# STM32H7A3x register map
File version: 1.8
CPU: CM7 r0p1, little endian, MPU, FPU, 4 interrupt priority bits
Registers are 32-bit, read-write, reset 0x0 unless marked. A register's access mark holds for its fields unless they carry their own. Offsets are from the block's base; [hi:lo] are bit positions; {n}, {i} and the like mark numbered series.

## DBGMCU — Microcontroller Debug Unit
Base 0x5C001000
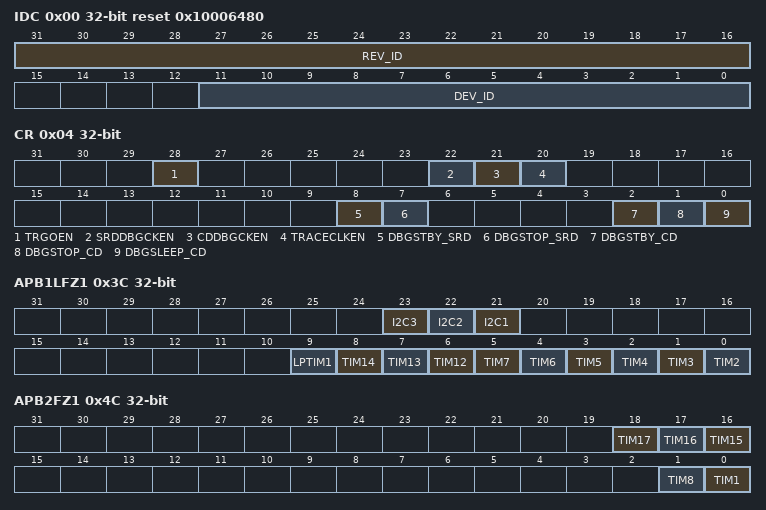
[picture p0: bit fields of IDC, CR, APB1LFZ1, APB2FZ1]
0x00 IDC ro reset 0x10006480 — DBGMCU Identity Code Register
  [31:16] REV_ID — Revision
  [11:0] DEV_ID — Device ID
0x04 CR — DBGMCU Configuration Register
  [28] TRGOEN — External trigger output enable
  [22] SRDDBGCKEN — SmartRun domain debug clock enable
  [21] CDDBGCKEN — CPU domain debug clock enable
  [20] TRACECLKEN — Trace port clock enable
  [8] DBGSTBY_SRD — debug in SmartRun domain Standby mode
  [7] DBGSTOP_SRD — debug in SmartRun domain Stop mode
  [2] DBGSTBY_CD — Allow D1 domain debug in Standby mode
  [1] DBGSTOP_CD — Allow D1 domain debug in Stop mode
  [0] DBGSLEEP_CD — Allow D1 domain debug in Sleep mode
0x34 APB3FZ1 — DBGMCU APB3 peripheral freeze register
  [6] WWDG — WWDG stop in debug
0x3C APB1LFZ1 — DBGMCU APB1L peripheral freeze register
  [23] I2C3 — I2C3 SMBUS timeout stop in debug
  [22] I2C2 — I2C2 SMBUS timeout stop in debug
  [21] I2C1 — I2C1 SMBUS timeout stop in debug
  [9] LPTIM1 — LPTIM1 stop in debug
  [8] TIM14 — TIM14 stop in debug
  [7] TIM13 — TIM13 stop in debug
  [6] TIM12 — TIM12 stop in debug
  [n-2] TIM{n} (n=2..7) — TIM{n} stop in debug
0x4C APB2FZ1 — DBGMCU APB2 peripheral freeze register
  [18] TIM17 — TIM17 stop in debug
  [17] TIM16 — TIM16 stop in debug
  [16] TIM15 — TIM15 stop in debug
  [1] TIM8 — TIM8 stop in debug
  [0] TIM1 — TIM1 stop in debug
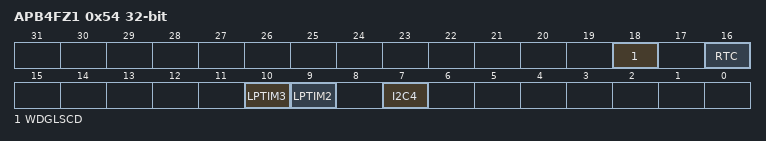
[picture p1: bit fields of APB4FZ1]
0x54 APB4FZ1 — DBGMCU APB4 peripheral freeze register
  [18] WDGLSCD — LS watchdog for CPU domain stop in debug
  [16] RTC — RTC stop in debug
  [10] LPTIM3 — LPTIM3 stop in debug
  [9] LPTIM2 — LPTIM2 stop in debug
  [7] I2C4 — I2C4 SMBUS timeout stop in debug

## MPU — Memory protection unit
Base 0xE000ED90
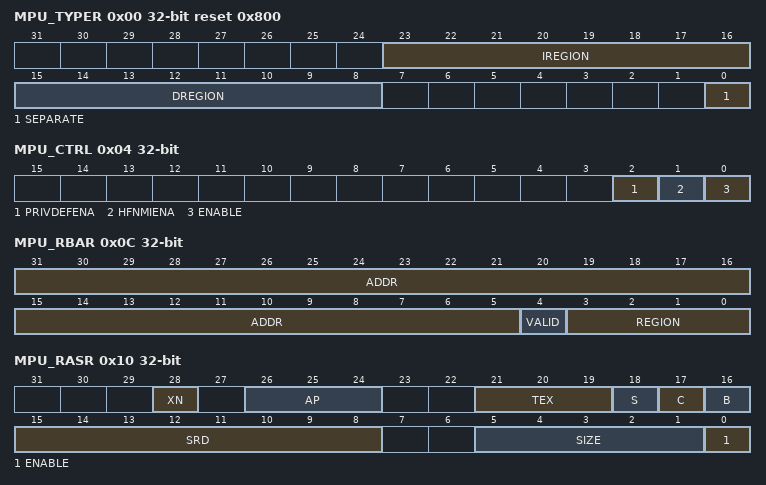
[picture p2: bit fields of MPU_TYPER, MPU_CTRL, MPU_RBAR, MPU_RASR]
0x00 MPU_TYPER ro reset 0x800 — MPU type register
  [23:16] IREGION — Number of MPU instruction regions
  [15:8] DREGION — Number of MPU data regions
  [0] SEPARATE — Separate flag
0x04 MPU_CTRL — MPU control register
  [2] PRIVDEFENA — Enable priviliged software access to default memory map
  [1] HFNMIENA — Enables the operation of MPU during hard fault
  [0] ENABLE — Enables the MPU
0x08 MPU_RNR — MPU region number register
  [7:0] REGION — MPU region
0x0C MPU_RBAR — MPU region base address register
  [31:5] ADDR — Region base address field
  [4] VALID — MPU region number valid
  [3:0] REGION — MPU region field
0x10 MPU_RASR — MPU region attribute and size register
  [28] XN — Instruction access disable bit
  [26:24] AP — Access permission
  [21:19] TEX — memory attribute
  [18] S — Shareable memory attribute
  [17] C — memory attribute
  [16] B — memory attribute
  [15:8] SRD — Subregion disable bits
  [5:1] SIZE — Size of the MPU protection region
  [0] ENABLE — Region enable bit.

## STK — SysTick timer
Base 0xE000E010
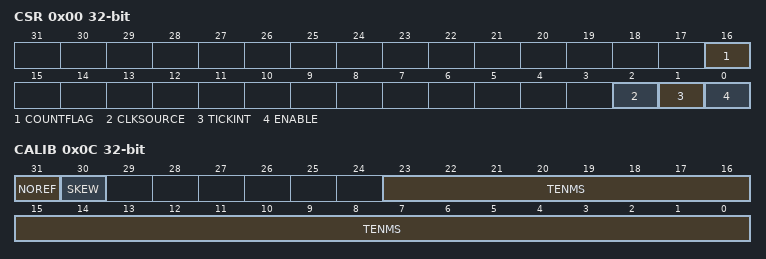
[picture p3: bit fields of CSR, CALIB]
0x00 CSR — SysTick control and status register
  [16] COUNTFLAG
  [2] CLKSOURCE — Clock source selection
  [1] TICKINT — SysTick exception request enable
  [0] ENABLE — Counter enable
0x04 RVR — SysTick reload value register
  [23:0] RELOAD — RELOAD value
0x08 CVR — SysTick current value register
  [23:0] CURRENT — Current counter value
0x0C CALIB — SysTick calibration value register
  [31] NOREF — NOREF flag. Reads as zero
  [30] SKEW — SKEW flag: Indicates whether the TENMS value is exact
  [23:0] TENMS — Calibration value

## NVIC_STIR — Nested vectored interrupt controller
Base 0xE000EF00
0x00 STIR — Software trigger interrupt register
  [8:0] INTID — Software generated interrupt ID

## FPU_CPACR — Floating point unit CPACR
Base 0xE000ED88
0x00 CPACR — Coprocessor access control register
  [23:20] CP

## SCB_ACTRL — System control block ACTLR
Base 0xE000E008
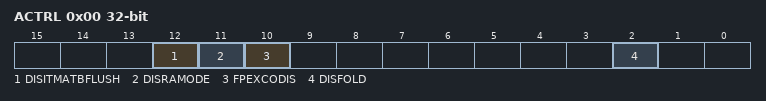
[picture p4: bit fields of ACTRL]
0x00 ACTRL — Auxiliary control register
  [12] DISITMATBFLUSH, [11] DISRAMODE, [10] FPEXCODIS, [2] DISFOLD
